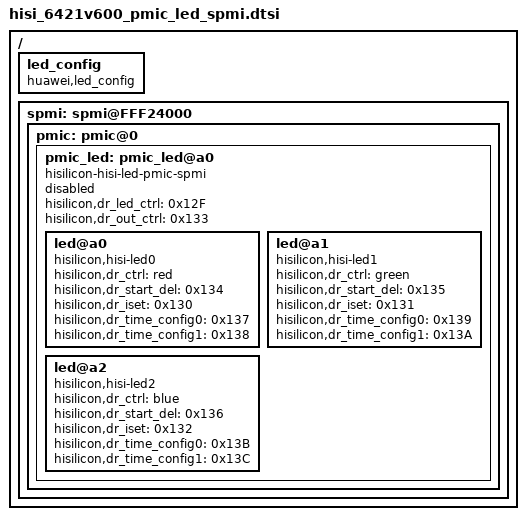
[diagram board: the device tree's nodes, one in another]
/*
 * Copyright (c) 2012-2013, The Linux Foundation. All rights reserved.
 *
 * This program is free software; you can redistribute it and/or modify
 * it under the terms of the GNU General Public License version 2 and
 * only version 2 as published by the Free Software Foundation.
 *
 * This program is distributed in the hope that it will be useful,
 * but WITHOUT ANY WARRANTY; without even the implied warranty of
 * MERCHANTABILITY or FITNESS FOR A PARTICULAR PURPOSE.  See the
 * GNU General Public License for more details.
 */

/ {
	led_config {
		compatible = "huawei,led_config";
		status = "ok";
	};

spmi: spmi@FFF24000 {
	pmic: pmic@0 {
		pmic_led: pmic_led@a0 {
			compatible = "hisilicon-hisi-led-pmic-spmi";
			status = "disabled";
			hisilicon,dr_led_ctrl = <0x12F>;
			hisilicon,dr_out_ctrl = <0x133>;

			led@a0 {
				compatible = "hisilicon,hisi-led0";
				hisilicon,dr_ctrl = "red";
				hisilicon,dr_start_del = <0x134>;
				hisilicon,dr_iset = <0x130>;
				hisilicon,dr_time_config0 = <0x137>;
				hisilicon,dr_time_config1 = <0x138>;
			};

			led@a1 {
				compatible = "hisilicon,hisi-led1";
				hisilicon,dr_ctrl = "green";
				hisilicon,dr_start_del = <0x135>;
				hisilicon,dr_iset = <0x131>;
				hisilicon,dr_time_config0 = <0x139>;
				hisilicon,dr_time_config1 = <0x13A>;
            };

			led@a2 {
				compatible = "hisilicon,hisi-led2";
				hisilicon,dr_ctrl = "blue";
				hisilicon,dr_start_del = <0x136>;
				hisilicon,dr_iset = <0x132>;
				hisilicon,dr_time_config0 = <0x13B>;
				hisilicon,dr_time_config1 = <0x13C>;
            };
        };
    };
};
};
